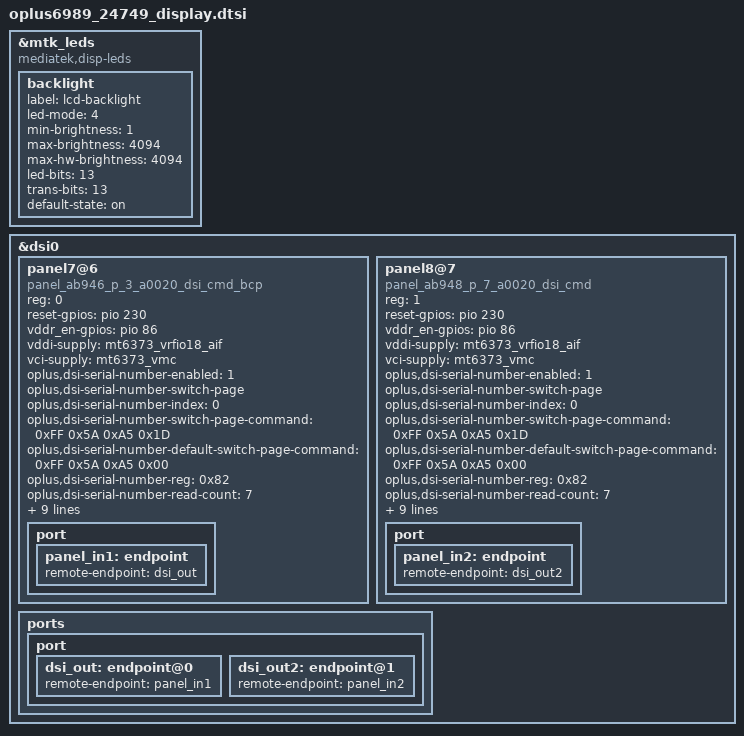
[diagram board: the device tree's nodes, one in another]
&mtk_leds {
	compatible = "mediatek,disp-leds";
	status = "okay";

	backlight {
		label = "lcd-backlight";
		led-mode = <4>;
		min-brightness = <1>;
		max-brightness = <4094>;
		max-hw-brightness = <4094>;
		led-bits = <13>;
		trans-bits = <13>;
		default-state = "on";
	};
};

&dsi0 {
	status = "okay";
	#address-cells = <1>;
	#size-cells = <0>;
	panel7@6 {
		compatible = "panel_ab946_p_3_a0020_dsi_cmd_bcp";
		reg = <0>;
		reset-gpios = <&pio 230 0>;
		vddr_en-gpios = <&pio 86 0>;
		vddi-supply = <&mt6373_vrfio18_aif>;
		vci-supply = <&mt6373_vmc>;
		oplus,dsi-serial-number-enabled=<1>;
		oplus,dsi-serial-number-switch-page;
		oplus,dsi-serial-number-index= <0>;
		oplus,dsi-serial-number-switch-page-command= <0xFF 0x5A 0xA5 0x1D>;
		oplus,dsi-serial-number-default-switch-page-command= <0xFF 0x5A 0xA5 0x00>;
		oplus,dsi-serial-number-reg= <0x82>;
		oplus,dsi-serial-number-read-count= <7>;
		/* 0 not support, 1 with switch, 2 Global high frequency pwm without switch */
		oplus,pwm-turbo-support = <2>;
		oplus,pwm-switch-backlight-threshold = <0x48A>;
		oplus,pwm-onepulse-support = <1>;
		oplus,pwm-onepulse-enabled = <0>;
		oplus-adfr-config = <0x201>;
		oplus-adfr-test-te-gpios = <&pio 222 0>;
		/* ofp config */
		oplus,ofp-fp-type = <0x10>;
		oplus,ofp-longrui-aod-config = <0x04>;
		res-switch = <2>;
		pinctrl-names = "default";
		port {
			panel_in1: endpoint {
				remote-endpoint = <&dsi_out>;
			};
		};
	};
	panel8@7 {
		compatible = "panel_ab948_p_7_a0020_dsi_cmd";
		reg = <1>;
		reset-gpios = <&pio 230 0>;
		vddr_en-gpios = <&pio 86 0>;
		vddi-supply = <&mt6373_vrfio18_aif>;
		vci-supply = <&mt6373_vmc>;
		oplus,dsi-serial-number-enabled=<1>;
		oplus,dsi-serial-number-switch-page;
		oplus,dsi-serial-number-index= <0>;
		oplus,dsi-serial-number-switch-page-command= <0xFF 0x5A 0xA5 0x1D>;
		oplus,dsi-serial-number-default-switch-page-command= <0xFF 0x5A 0xA5 0x00>;
		oplus,dsi-serial-number-reg= <0x82>;
		oplus,dsi-serial-number-read-count= <7>;
		/* 0 not support, 1 with switch, 2 Global high frequency pwm without switch */
		oplus,pwm-turbo-support = <2>;
		oplus,pwm-switch-backlight-threshold = <0x48A>;
		oplus,pwm-onepulse-support = <1>;
		oplus,pwm-onepulse-enabled = <0>;
		oplus-adfr-config = <0x201>;
		oplus-adfr-test-te-gpios = <&pio 222 0>;
		/* ofp config */
		oplus,ofp-fp-type = <0x10>;
		oplus,ofp-longrui-aod-config = <0x04>;
		res-switch = <2>;
		pinctrl-names = "default";
		port {
			panel_in2: endpoint {
				remote-endpoint = <&dsi_out2>;
			};
		};
	};

	ports {
		port {
			dsi_out: endpoint@0 {
				remote-endpoint = <&panel_in1>;
			};

			dsi_out2: endpoint@1 {
				remote-endpoint = <&panel_in2>;
			};

		};
	};
};
